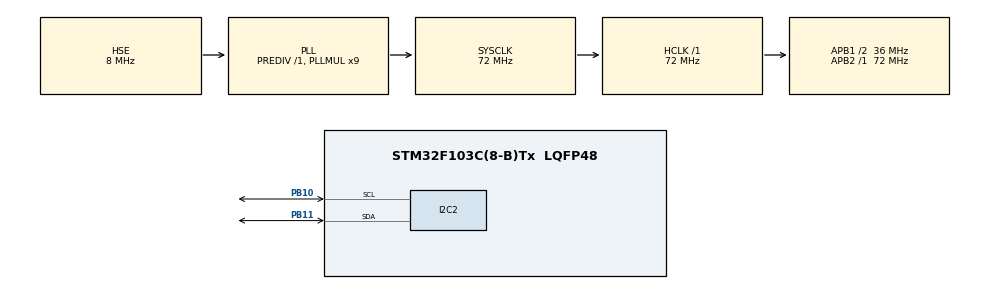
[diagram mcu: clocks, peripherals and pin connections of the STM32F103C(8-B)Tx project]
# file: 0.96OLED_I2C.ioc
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Mcu.Family=STM32F1
Mcu.Name=STM32F103C(8-B)Tx
Mcu.Package=LQFP48
NVIC.PriorityGroup=NVIC_PRIORITYGROUP_4
PA13.Mode=Serial_Wire
PA13.Signal=SYS_JTMS-SWDIO
PA14.Mode=Serial_Wire
PA14.Signal=SYS_JTCK-SWCLK
PB10.Mode=I2C
PB10.Signal=I2C2_SCL
PB11.Mode=I2C
PB11.Signal=I2C2_SDA
PD0-OSC_IN.Mode=HSE-External-Oscillator
PD0-OSC_IN.Signal=RCC_OSC_IN
PD1-OSC_OUT.Mode=HSE-External-Oscillator
PD1-OSC_OUT.Signal=RCC_OSC_OUT
ProjectManager.HeapSize=0x200
ProjectManager.StackSize=0x400
ProjectManager.TargetToolchain=MDK-ARM V5.32
RCC.AHBFreq_Value=72000000
RCC.APB1CLKDivider=RCC_HCLK_DIV2
RCC.APB1Freq_Value=36000000
RCC.APB1TimFreq_Value=72000000
RCC.APB2Freq_Value=72000000
RCC.APB2TimFreq_Value=72000000
RCC.HCLKFreq_Value=72000000
RCC.PLLMUL=RCC_PLL_MUL9
RCC.PLLSourceVirtual=RCC_PLLSOURCE_HSE
RCC.SYSCLKFreq_VALUE=72000000
RCC.SYSCLKSource=RCC_SYSCLKSOURCE_PLLCLK
RCC.USBFreq_Value=72000000
TIM1.Prescaler=71
VP_TIM1_VS_ClockSourceINT.Mode=Internal
board=custom

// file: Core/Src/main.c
/* USER CODE BEGIN Header */
/**
  ******************************************************************************
  * @file           : main.c
  * @brief          : Main program body
  ******************************************************************************
  */
/* USER CODE END Header */
#include "main.h"
#include "i2c.h"
#include "tim.h"
#include "gpio.h"

/* USER CODE BEGIN Includes */
#include "stm32_u8g2.h"
#include <stdio.h>
/* USER CODE END Includes */

void SystemClock_Config(void);

/* USER CODE BEGIN 0 */
//??:??? 16*16
unsigned char hz_zhong[] = {
0x04,0x80,0x08,0x80,0x34,0x80,0x87,0xFB,0x24,0x84,0x88,0x00,0x00,0x00,0x09,0x30,
0x08,0x40,0x40,0x7F,0x08,0x40,0x08,0x40,0x10,0x40,0x00,0x00,0x00,0x00,0x00,0x00
};

unsigned char hz_wei[] = {
0x00,0x80,0x01,0x00,0x06,0x00,0x1F,0x3F,0x30,0x00,0x10,0x40,0x12,0x40,0x12,0x40,
0x12,0x40,0x40,0x7F,0x39,0x12,0x40,0x12,0x40,0x48,0x44,0x10,0x00,0x78,0x00,0x00
};

unsigned char hz_huang[] = {
0x01,0x01,0x08,0x06,0x06,0x00,0x18,0x18,0x08,0x08,0x10,0x08,0x82,0x33,0x00,0x92,
0x24,0x92,0x6A,0x92,0x4A,0x92,0x24,0x92,0x2A,0x92,0x38,0x92,0x00,0x82,0x00,0x00
};
/* USER CODE END 0 */

int main(void)
{

  /* MCU Configuration--------------------------------------------------------*/
  HAL_Init();

  SystemClock_Config();

  MX_GPIO_Init();
  MX_I2C2_Init();
  MX_TIM1_Init();

  /* USER CODE BEGIN 2 */
  u8g2_t u8g2;
  HAL_TIM_Base_Start(&htim1);
  u8g2Init(&u8g2);
  /* USER CODE END 2 */

  /* Infinite loop */
  while (1)
  {

    /* USER CODE BEGIN 3 */
    static uint8_t mode = 1;
    static int16_t scroll_x = 0;
    static int16_t scroll_y = 0;
    static uint8_t dir = 0;
    static uint8_t anim_step = 0;

    switch(mode)
    {
        //=====??1:U8G2 DEMO??=====
        case 1:
            u8g2_ClearBuffer(&u8g2);
            u8g2_SetFont(&u8g2, u8g2_font_10x20_tf);
            u8g2_DrawStr(&u8g2, 0, 18, "U8G2 DEMO");
            u8g2_SetFont(&u8g2, u8g2_font_6x10_tf);
            u8g2_DrawFrame(&u8g2, 0, 24, 60, 30);
            u8g2_DrawCircle(&u8g2, 90, 38, 12, U8G2_DRAW_ALL);
            u8g2_DrawLine(&u8g2, 0, 60, 127, 60);
            u8g2_SendBuffer(&u8g2);
            HAL_Delay(2500);
            mode = 2;
            break;

        //=====??2:??+??=====
        case 2:
            u8g2_ClearBuffer(&u8g2);
            u8g2_SetFont(&u8g2, u8g2_font_ncenB10_tf);
            u8g2_DrawStr(&u8g2, 5, 15, "632407030314");
            u8g2_DrawXBMP(&u8g2, 10, 35, 16,16,hz_zhong);
            u8g2_DrawXBMP(&u8g2, 30, 35, 16,16,hz_wei);
            u8g2_DrawXBMP(&u8g2, 50, 35, 16,16,hz_huang);
            u8g2_SendBuffer(&u8g2);
            HAL_Delay(2500);
            mode = 3;
            scroll_x = 0;
            scroll_y = 0;
            dir = 0;
            break;

        //=====??3:?????????=====
        case 3:
            u8g2_ClearBuffer(&u8g2);
            u8g2_SetFont(&u8g2, u8g2_font_8x13_tf);
            if(dir == 0)
            {
                //??
                u8g2_DrawStr(&u8g2, scroll_x, 32, "SCROLL TEST");
                scroll_x += 1;
                if(scroll_x > 128) { scroll_x = -60; dir = 1; }
            }
            else if(dir == 1)
            {
                //??
                u8g2_DrawStr(&u8g2, scroll_x, 32, "SCROLL TEST");
                scroll_x -= 1;
                if(scroll_x < -60) { scroll_x = 128; dir = 2; }
            }
            else if(dir == 2)
            {
                //??
                u8g2_DrawStr(&u8g2, 20, scroll_y, "SCROLL TEST");
                scroll_y += 1;
                if(scroll_y > 64) { scroll_y = -15; dir = 3; }
            }
            else if(dir == 3)
            {
                //??
                u8g2_DrawStr(&u8g2, 20, scroll_y, "SCROLL TEST");
                scroll_y -= 1;
                if(scroll_y < -15) { scroll_y = 64; dir = 0; }
            }
            u8g2_SendBuffer(&u8g2);
            HAL_Delay(35);
            anim_step ++;
            if(anim_step > 220)
            {
                anim_step = 0;
                mode = 4;
            }
            break;

        //=====??4:??????(????)=====
        case 4:
            u8g2_ClearBuffer(&u8g2);
            uint8_t jump_y;
            if(anim_step < 15) jump_y = 20;
            else if(anim_step < 30) jump_y = 12;
            else if(anim_step < 45) jump_y = 20;
            else jump_y = 28;

            //???:?+??+??
            u8g2_DrawCircle(&u8g2, 64, jump_y, 6, U8G2_DRAW_ALL);
            u8g2_DrawLine(&u8g2, 64, jump_y+6, 64, jump_y+18);
            u8g2_DrawLine(&u8g2, 64, jump_y+9, 54, jump_y+14);
            u8g2_DrawLine(&u8g2, 64, jump_y+9, 74, jump_y+14);
            u8g2_DrawLine(&u8g2, 64, jump_y+18, 54, jump_y+28);
            u8g2_DrawLine(&u8g2, 64, jump_y+18, 74, jump_y+28);
            u8g2_SendBuffer(&u8g2);
            HAL_Delay(60);
            anim_step ++;
            if(anim_step > 80)
            {
                anim_step = 0;
                mode = 1;
            }
            break;
    }
    /* USER CODE END 3 */
  }
  return 0;
}

void SystemClock_Config(void)
{
  RCC_OscInitTypeDef RCC_OscInitStruct = {0};
  RCC_ClkInitTypeDef RCC_ClkInitStruct = {0};

  RCC_OscInitStruct.OscillatorType = RCC_OSCILLATORTYPE_HSE;
  RCC_OscInitStruct.HSEState = RCC_HSE_ON;
  RCC_OscInitStruct.HSEPredivValue = RCC_HSE_PREDIV_DIV1;
  RCC_OscInitStruct.HSIState = RCC_HSI_ON;
  RCC_OscInitStruct.PLL.PLLState = RCC_PLL_ON;
  RCC_OscInitStruct.PLL.PLLSource = RCC_PLLSOURCE_HSE;
  RCC_OscInitStruct.PLL.PLLMUL = RCC_PLL_MUL9;
  if (HAL_RCC_OscConfig(&RCC_OscInitStruct) != HAL_OK)
  {
    Error_Handler();
  }

  RCC_ClkInitStruct.ClockType = RCC_CLOCKTYPE_HCLK|RCC_CLOCKTYPE_SYSCLK
                              |RCC_CLOCKTYPE_PCLK1|RCC_CLOCKTYPE_PCLK2;
  RCC_ClkInitStruct.SYSCLKSource = RCC_SYSCLKSOURCE_PLLCLK;
  RCC_ClkInitStruct.AHBCLKDivider = RCC_SYSCLK_DIV1;
  RCC_ClkInitStruct.APB1CLKDivider = RCC_HCLK_DIV2;
  RCC_ClkInitStruct.APB2CLKDivider = RCC_HCLK_DIV1;

  if (HAL_RCC_ClockConfig(&RCC_ClkInitStruct, FLASH_LATENCY_2) != HAL_OK)
  {
    Error_Handler();
  }
}

void Error_Handler(void)
{
  __disable_irq();
  while (1)
  {
  }
}

/************************ (C) COPYRIGHT STMicroelectronics *****END OF FILE****/
